# STM32F373 register map
File version: 1.7
CPU: CM4 r1p0, little endian, MPU, FPU, 4 interrupt priority bits
Registers are 32-bit, read-write, reset 0x0 unless marked. A register's access mark holds for its fields unless they carry their own. Offsets are from the block's base; [hi:lo] are bit positions; {n}, {i} and the like mark numbered series; 'fields as' and 'values as' point back to an identical list.

## RCC — Reset and clock control
Base 0x40021000
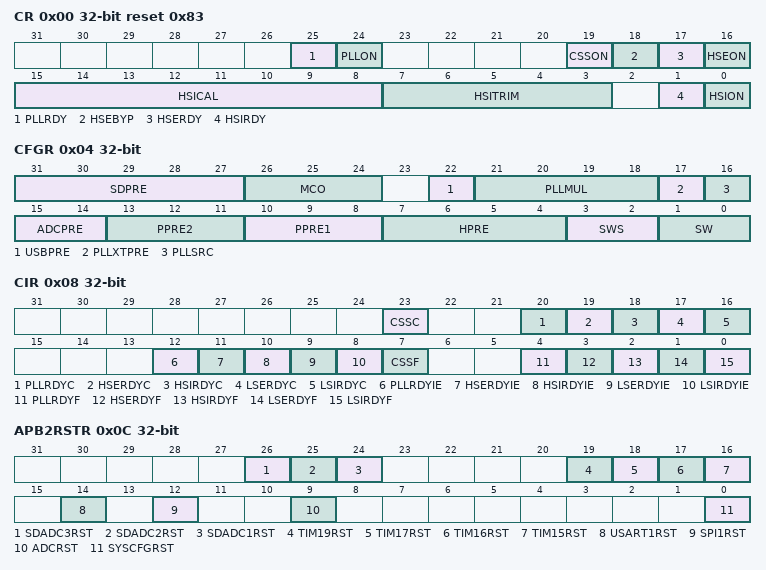
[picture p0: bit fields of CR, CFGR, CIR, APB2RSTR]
0x00 CR access per field reset 0x83 — Clock control register
  [25] PLLRDY ro — PLL clock ready flag
    0=NotReady (Clock not ready); 1=Ready (Clock ready)
  [24] PLLON rw — PLL enable
    0=Off (Clock Off); 1=On (Clock On)
  [19] CSSON rw — Clock Security System enable
    0=Off (Clock security system disabled (clock detector OFF)); 1=On (Clock security system enable (clock detector ON if the HSE is ready, OFF if not))
  [18] HSEBYP rw — External High Speed clock Bypass
    0=NotBypassed (HSE crystal oscillator not bypassed); 1=Bypassed (HSE crystal oscillator bypassed with external clock)
  [17] HSERDY ro — External High Speed clock ready flag
    0=NotReady (Clock not ready); 1=Ready (Clock ready)
  [16] HSEON rw — External High Speed clock enable
    0=Off (Clock Off); 1=On (Clock On)
  [15:8] HSICAL ro — Internal High Speed clock Calibration
  [7:3] HSITRIM rw — Internal High Speed clock trimming
  [1] HSIRDY ro — Internal High Speed clock ready flag
    0=NotReady (Clock not ready); 1=Ready (Clock ready)
  [0] HSION rw — Internal High Speed clock enable
    0=Off (Clock Off); 1=On (Clock On)
0x04 CFGR access per field — Clock configuration register (RCC_CFGR)
  [31:27] SDPRE rw — SDADC prescaler
    17=Div4 (SYSCLK divided by 4); 18=Div6 (SYSCLK divided by 6); 19=Div8 (SYSCLK divided by 8); 20=Div10 (SYSCLK divided by 10); 21=Div12 (SYSCLK divided by 12); 22=Div14 (SYSCLK divided by 14); 23=Div16 (SYSCLK divided by 16); 24=Div20 (SYSCLK divided by 20); 25=Div24 (SYSCLK divided by 24); 26=Div28 (SYSCLK divided by 28); 27=Div32 (SYSCLK divided by 32); 28=Div36 (SYSCLK divided by 36); 29=Div40 (SYSCLK divided by 40); 30=Div44 (SYSCLK divided by 44); 31=Div48 (SYSCLK divided by 48); other=Div2 (SYSCLK divided by 2)
  [26:24] MCO rw — Microcontroller clock output
    0=NoMCO (MCO output disabled, no clock on MCO); 2=LSI (Internal low speed (LSI) oscillator clock selected); 3=LSE (External low speed (LSE) oscillator clock selected); 4=SYSCLK (System clock selected); 5=HSI (Internal RC 8 MHz (HSI) oscillator clock selected); 6=HSE (External 4-32 MHz (HSE) oscillator clock selected); 7=PLL (PLL clock selected (divided by 1 or 2, depending en PLLNODIV))
  [22] USBPRE rw — USB prescaler
    0=DIV1_5 (PLL clock is divided by 1.5); 1=DIV1 (PLL clock is not divided)
  [21:18] PLLMUL rw — PLL Multiplication Factor
    {v}=Mul{v+2} (PLL input clock x{v+2}) (v=0..14); 15=Mul16x (PLL input clock x16)
  [17] PLLXTPRE rw — HSE divider for PLL entry
    0=Div1 (HSE clock not divided); 1=Div2 (HSE clock divided by 2)
  [16] PLLSRC rw — PLL entry clock source
    0=HSI_Div2 (HSI divided by 2 selected as PLL input clock); 1=HSE_Div_PREDIV (HSE divided by PREDIV selected as PLL input clock)
  [15:14] ADCPRE rw — ADC prescaler
    0=Div2 (PCLK divided by 2); 1=Div4 (PCLK divided by 4); 2=Div6 (PCLK divided by 6); 3=Div8 (PCLK divided by 8)
  [13:11] PPRE2 rw — APB high speed prescaler (APB2)
    4=Div2 (HCLK divided by 2); 5=Div4 (HCLK divided by 4); 6=Div8 (HCLK divided by 8); 7=Div16 (HCLK divided by 16); other=Div1 (HCLK not divided)
  [10:8] PPRE1 rw — APB Low speed prescaler (APB1)
    values as PPRE2
  [7:4] HPRE rw — AHB prescaler
    8=Div2 (SYSCLK divided by 2); 9=Div4 (SYSCLK divided by 4); 10=Div8 (SYSCLK divided by 8); 11=Div16 (SYSCLK divided by 16); 12=Div64 (SYSCLK divided by 64); 13=Div128 (SYSCLK divided by 128); 14=Div256 (SYSCLK divided by 256); 15=Div512 (SYSCLK divided by 512); other=Div1 (SYSCLK not divided)
  [3:2] SWS ro — System Clock Switch Status
    0=HSI (HSI oscillator used as system clock); 1=HSE (HSE oscillator used as system clock); 2=PLL (PLL used as system clock)
  [1:0] SW rw — System clock Switch
    0=HSI (HSI selected as system clock); 1=HSE (HSE selected as system clock); 2=PLL (PLL selected as system clock)
0x08 CIR access per field — Clock interrupt register (RCC_CIR)
  [23] CSSC wo — Clock security system interrupt clear
    1=Clear CSSF flag
  [20] PLLRDYC wo — PLL Ready Interrupt Clear
    1=Clear interrupt flag
  [19] HSERDYC wo — HSE Ready Interrupt Clear
    1=Clear interrupt flag
  [18] HSIRDYC wo — HSI Ready Interrupt Clear
    1=Clear interrupt flag
  [17] LSERDYC wo — LSE Ready Interrupt Clear
    1=Clear interrupt flag
  [16] LSIRDYC wo — LSI Ready Interrupt Clear
    1=Clear interrupt flag
  [12] PLLRDYIE rw — PLL Ready Interrupt Enable
    0=Disabled (Interrupt disabled); 1=Enabled (Interrupt enabled)
  [11] HSERDYIE rw — HSE Ready Interrupt Enable
    values as PLLRDYIE
  [10] HSIRDYIE rw — HSI Ready Interrupt Enable
    values as PLLRDYIE
  [9] LSERDYIE rw — LSE Ready Interrupt Enable
    values as PLLRDYIE
  [8] LSIRDYIE rw — LSI Ready Interrupt Enable
    values as PLLRDYIE
  [7] CSSF ro — Clock Security System Interrupt flag
    0=NotInterrupted (No clock security interrupt caused by HSE clock failure); 1=Interrupted (Clock security interrupt caused by HSE clock failure)
  [4] PLLRDYF ro — PLL Ready Interrupt flag
    0=NotInterrupted (No clock ready interrupt); 1=Interrupted (Clock ready interrupt)
  [3] HSERDYF ro — HSE Ready Interrupt flag
    values as PLLRDYF
  [2] HSIRDYF ro — HSI Ready Interrupt flag
    values as PLLRDYF
  [1] LSERDYF ro — LSE Ready Interrupt flag
    values as PLLRDYF
  [0] LSIRDYF ro — LSI Ready Interrupt flag
    values as PLLRDYF
0x0C APB2RSTR — APB2 peripheral reset register (RCC_APB2RSTR)
  [all] fields
    1=Reset the selected module
  [26] SDADC3RST — SDADC3 (Sigma delta ADC 3) reset
  [25] SDADC2RST — SDADC2 (Sigma delta ADC 2) reset
  [24] SDADC1RST — SDADC1 (Sigma delta ADC 1) reset
  [19] TIM19RST — TIM19 timer reset
  [18] TIM17RST — TIM17 timer reset
  [17] TIM16RST — TIM16 timer reset
  [16] TIM15RST — TIM15 timer reset
  [14] USART1RST — USART1 reset
  [12] SPI1RST — SPI 1 reset
  [9] ADCRST — ADC interface reset
  [0] SYSCFGRST — SYSCFG and COMP reset
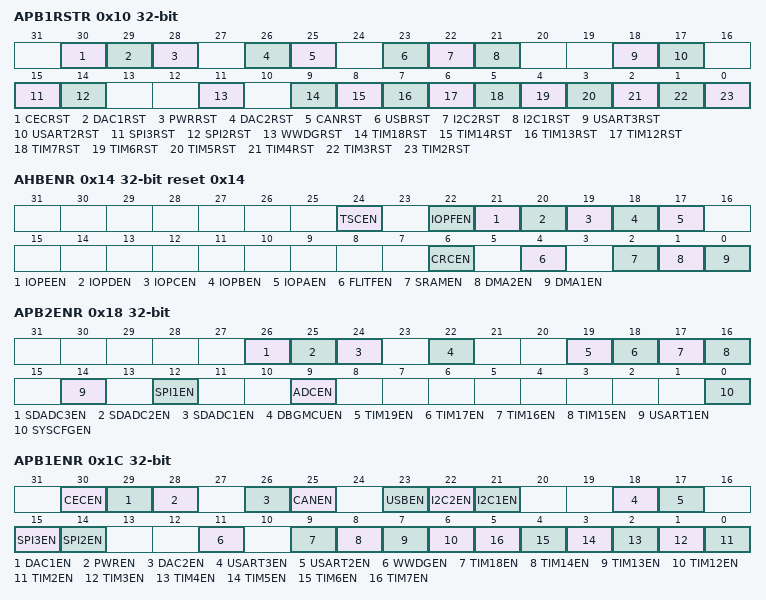
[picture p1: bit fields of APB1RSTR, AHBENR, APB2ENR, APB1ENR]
0x10 APB1RSTR — APB1 peripheral reset register (RCC_APB1RSTR)
  [all] fields
    1=Reset the selected module
  [30] CECRST — HDMI CEC reset
  [29] DAC1RST — DAC interface reset
  [28] PWRRST — Power interface reset
  [26] DAC2RST — DAC3 reset
  [25] CANRST — CAN reset
  [23] USBRST — USB reset
  [22] I2C2RST — I2C2 reset
  [21] I2C1RST — I2C1 reset
  [18] USART3RST — USART3 reset
  [17] USART2RST — USART 2 reset
  [15] SPI3RST — SPI3 reset
  [14] SPI2RST — SPI2 reset
  [11] WWDGRST — Window watchdog reset
  [9] TIM18RST — Timer 18 reset
  [8] TIM14RST — Timer 14 reset
  [7] TIM13RST — Timer 13 reset
  [6] TIM12RST — Timer 12 reset
  [5] TIM7RST — Timer 7 reset
  [4] TIM6RST — Timer 6 reset
  [3] TIM5RST — Timer 5 reset
  [2] TIM4RST — Timer 14 reset
  [1] TIM3RST — Timer 3 reset
  [0] TIM2RST — Timer 2 reset
0x14 AHBENR reset 0x14 — AHB Peripheral Clock enable register (RCC_AHBENR)
  [all] fields
    0=Disabled (The selected clock is disabled); 1=Enabled (The selected clock is enabled)
  [24] TSCEN — Touch sensing controller clock enable
  [22] IOPFEN — I/O port F clock enable
  [21] IOPEEN — I/O port E clock enable
  [20] IOPDEN — I/O port D clock enable
  [19] IOPCEN — I/O port C clock enable
  [18] IOPBEN — I/O port B clock enable
  [17] IOPAEN — I/O port A clock enable
  [6] CRCEN — CRC clock enable
  [4] FLITFEN — FLITF clock enable
  [2] SRAMEN — SRAM interface clock enable
  [1] DMA2EN — DMA2 clock enable
  [0] DMA1EN — DMA1 clock enable
0x18 APB2ENR — APB2 peripheral clock enable register (RCC_APB2ENR)
  [all] fields
    values as the fields of AHBENR
  [26] SDADC3EN — SDADC3 (Sigma Delta ADC 3) clock enable
  [25] SDADC2EN — SDADC2 (Sigma Delta ADC 2) clock enable
  [24] SDADC1EN — SDADC1 (Sigma Delta ADC 1) clock enable
  [22] DBGMCUEN — MCU debug module clock enable
  [19] TIM19EN — TIM19 timer clock enable
  [18] TIM17EN — TIM17 timer clock enable
  [17] TIM16EN — TIM16 timer clock enable
  [16] TIM15EN — TIM15 timer clock enable
  [14] USART1EN — USART1 clock enable
  [12] SPI1EN — SPI 1 clock enable
  [9] ADCEN — ADC 1 interface clock enable
  [0] SYSCFGEN — SYSCFG clock enable
0x1C APB1ENR — APB1 peripheral clock enable register (RCC_APB1ENR)
  [all] fields
    values as the fields of AHBENR
  [30] CECEN — HDMI CEC interface clock enable
  [29] DAC1EN — DAC interface clock enable
  [28] PWREN — Power interface clock enable
  [26] DAC2EN — DAC3 interface clock enable
  [25] CANEN — CAN clock enable
  [23] USBEN — USB clock enable
  [22] I2C2EN — I2C 2 clock enable
  [21] I2C1EN — I2C 1 clock enable
  [18] USART3EN — USART 3 clock enable
  [17] USART2EN — USART 2 clock enable
  [15] SPI3EN — SPI 3 clock enable
  [14] SPI2EN — SPI 2 clock enable
  [11] WWDGEN — Window watchdog clock enable
  [9] TIM18EN — Timer 18 clock enable
  [8] TIM14EN — Timer 14 clock enable
  [7] TIM13EN — Timer 13 clock enable
  [6] TIM12EN — Timer 12 clock enable
  [n-2] TIM{n}EN (n=2..7) — Timer {n} clock enable
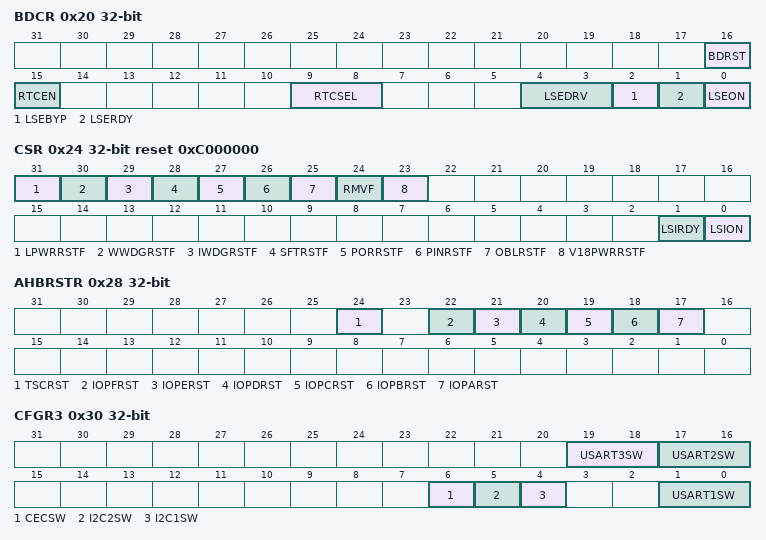
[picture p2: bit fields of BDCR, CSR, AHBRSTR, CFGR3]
0x20 BDCR access per field — Backup domain control register (RCC_BDCR)
  [16] BDRST rw — Backup domain software reset
    0=Disabled (Reset not activated); 1=Enabled (Reset the entire RTC domain)
  [15] RTCEN rw — RTC clock enable
    0=Disabled (RTC clock disabled); 1=Enabled (RTC clock enabled)
  [9:8] RTCSEL rw — RTC clock source selection
    0=NoClock; 1=LSE (LSE oscillator clock used as RTC clock); 2=LSI (LSI oscillator clock used as RTC clock); 3=HSE (HSE oscillator clock divided by a prescaler used as RTC clock)
  [4:3] LSEDRV rw — LSE oscillator drive capability
    0=Low (Low drive capacity); 1=Medium-high drive capacity; 2=Medium-low drive capacity; 3=High drive capacity
  [2] LSEBYP rw — External Low Speed oscillator bypass
    0=NotBypassed (LSE crystal oscillator not bypassed); 1=Bypassed (LSE crystal oscillator bypassed with external clock)
  [1] LSERDY ro — External Low Speed oscillator ready
    0=NotReady (LSE oscillator not ready); 1=Ready (LSE oscillator ready)
  [0] LSEON rw — External Low Speed oscillator enable
    0=Off (LSE oscillator Off); 1=On (LSE oscillator On)
0x24 CSR access not given reset 0xC000000 — Control/status register (RCC_CSR)
  [31] LPWRRSTF rw — Low-power reset flag
    on read: 0=No reset has occured; 1=Reset (A reset has occured)
  [30] WWDGRSTF rw — Window watchdog reset flag
    values as LPWRRSTF
  [29] IWDGRSTF rw — Independent watchdog reset flag
    values as LPWRRSTF
  [28] SFTRSTF rw — Software reset flag
    values as LPWRRSTF
  [27] PORRSTF rw — POR/PDR reset flag
    values as LPWRRSTF
  [26] PINRSTF rw — PIN reset flag
    values as LPWRRSTF
  [25] OBLRSTF rw — Option byte loader reset flag
    values as LPWRRSTF
  [24] RMVF rw — Remove reset flag
    on write: 1=Clears the reset flag
  [23] V18PWRRSTF — Reset flag of the 1.8 V domain
    values as LPWRRSTF
  [1] LSIRDY ro — Internal low speed oscillator ready
    0=NotReady (LSI oscillator not ready); 1=Ready (LSI oscillator ready)
  [0] LSION rw — Internal low speed oscillator enable
    0=Off (LSI oscillator Off); 1=On (LSI oscillator On)
0x28 AHBRSTR — AHB peripheral reset register
  [all] fields
    1=Reset the selected module
  [24] TSCRST — Touch sensing controller reset
  [22] IOPFRST — I/O port F reset
  [21] IOPERST — I/O port E reset
  [20] IOPDRST — I/O port D reset
  [19] IOPCRST — I/O port C reset
  [18] IOPBRST — I/O port B reset
  [17] IOPARST — I/O port A reset
0x2C CFGR2 — Clock configuration register 2
  [3:0] PREDIV — PREDIV division factor
    0=Div1 (PREDIV input clock not divided); {v}=Div{v+1} (PREDIV input clock divided by {v+1}) (v=1..15)
0x30 CFGR3 — Clock configuration register 3
  [19:18] USART3SW — USART3 clock source selection
    0=PCLK (PCLK selected as USART clock source); 1=SYSCLK (SYSCLK selected as USART clock source); 2=LSE (LSE selected as USART clock source); 3=HSI (HSI selected as USART clock source)
  [17:16] USART2SW — USART2 clock source selection
    values as USART3SW
  [6] CECSW — HDMI CEC clock source selection
    0=HSI_Div244 (HSI clock divided by 244 selected as CEC clock source); 1=LSE (LSE clock selected as CEC clock source)
  [5] I2C2SW — I2C2 clock source selection
    0=HSI (HSI clock selected as I2C clock source); 1=SYSCLK (SYSCLK clock selected as I2C clock source)
  [4] I2C1SW — I2C1 clock source selection
    values as I2C2SW
  [1:0] USART1SW — USART1 clock source selection
    values as USART3SW
